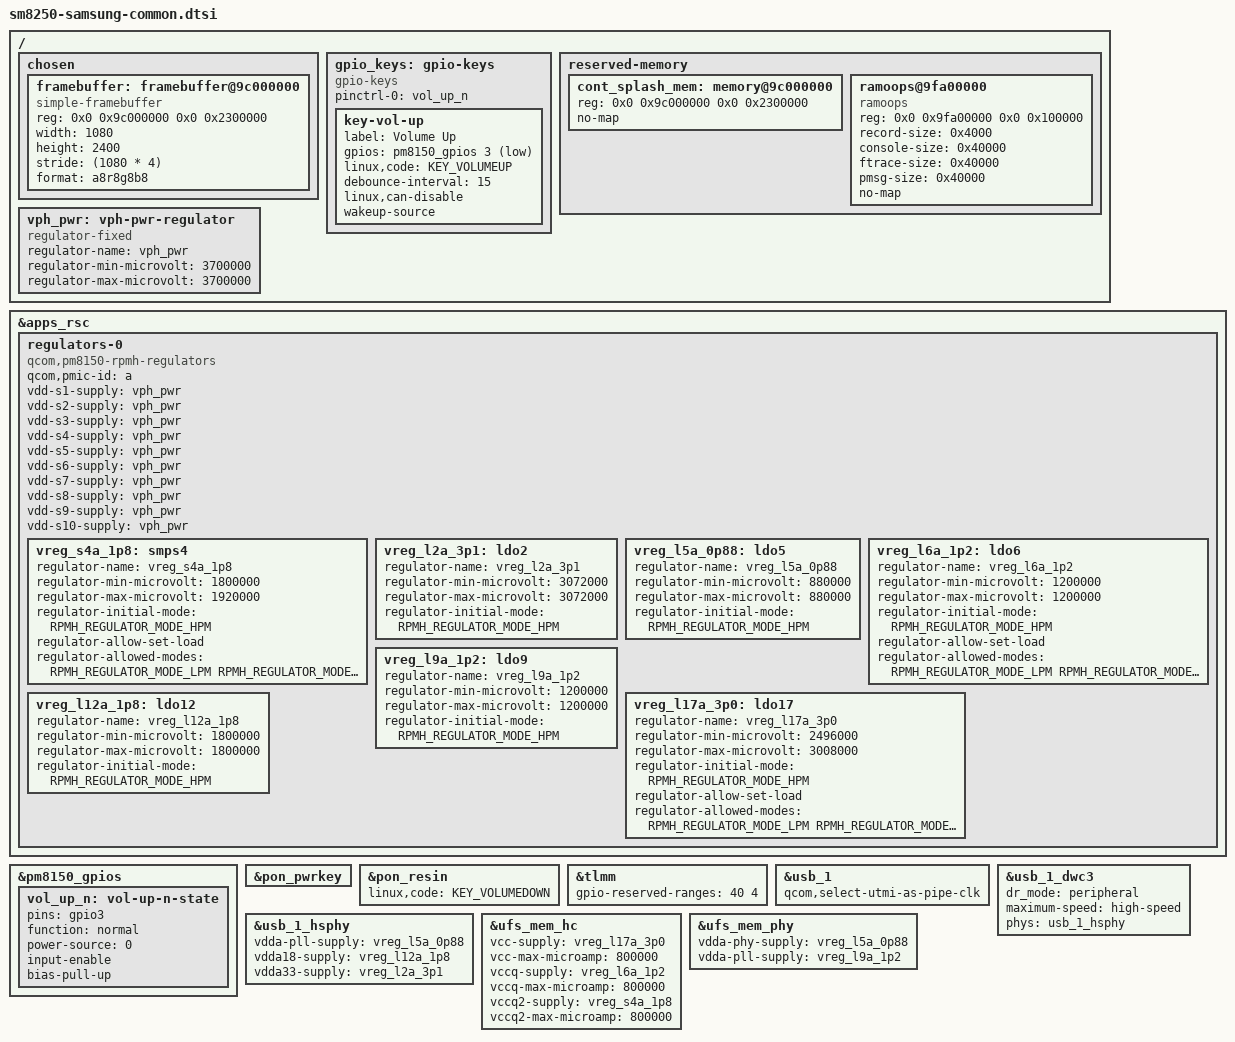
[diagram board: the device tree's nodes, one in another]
// SPDX-License-Identifier: GPL-2.0-only

/dts-v1/;

#include <dt-bindings/regulator/qcom,rpmh-regulator.h>
#include "sm8250.dtsi"
#include "pm8150.dtsi"

/ {
	chosen {
		#address-cells = <2>;
		#size-cells = <2>;
		ranges;

		framebuffer: framebuffer@9c000000 {
			compatible = "simple-framebuffer";
			reg = <0x0 0x9c000000 0x0 0x2300000>;
			width = <1080>;
			height = <2400>;
			stride = <(1080 * 4)>;
			format = "a8r8g8b8";
		};
	};

	gpio_keys: gpio-keys {
		compatible = "gpio-keys";

		pinctrl-names = "default";
		pinctrl-0 = <&vol_up_n>;

		key-vol-up {
			label = "Volume Up";
			gpios = <&pm8150_gpios 3 GPIO_ACTIVE_LOW>;
			linux,code = <KEY_VOLUMEUP>;
			debounce-interval = <15>;
			linux,can-disable;
			wakeup-source;
		};
	};

	reserved-memory {
		cont_splash_mem: memory@9c000000 {
			reg = <0x0 0x9c000000 0x0 0x2300000>;
			no-map;
		};

		ramoops@9fa00000 {
			compatible = "ramoops";
			reg = <0x0 0x9fa00000 0x0 0x100000>;
			record-size = <0x4000>;
			console-size = <0x40000>;
			ftrace-size = <0x40000>;
			pmsg-size = <0x40000>;
			no-map;
		};
	};

	vph_pwr: vph-pwr-regulator {
		compatible = "regulator-fixed";
		regulator-name = "vph_pwr";
		regulator-min-microvolt = <3700000>;
		regulator-max-microvolt = <3700000>;
	};
};

&apps_rsc {
	regulators-0 {
		compatible = "qcom,pm8150-rpmh-regulators";
		qcom,pmic-id = "a";

		vdd-s1-supply = <&vph_pwr>;
		vdd-s2-supply = <&vph_pwr>;
		vdd-s3-supply = <&vph_pwr>;
		vdd-s4-supply = <&vph_pwr>;
		vdd-s5-supply = <&vph_pwr>;
		vdd-s6-supply = <&vph_pwr>;
		vdd-s7-supply = <&vph_pwr>;
		vdd-s8-supply = <&vph_pwr>;
		vdd-s9-supply = <&vph_pwr>;
		vdd-s10-supply = <&vph_pwr>;

		vreg_s4a_1p8: smps4 {
			regulator-name = "vreg_s4a_1p8";
			regulator-min-microvolt = <1800000>;
			regulator-max-microvolt = <1920000>;
			regulator-initial-mode = <RPMH_REGULATOR_MODE_HPM>;
			regulator-allow-set-load;
			regulator-allowed-modes = <RPMH_REGULATOR_MODE_LPM
						   RPMH_REGULATOR_MODE_HPM>;
		};

		vreg_l2a_3p1: ldo2 {
			regulator-name = "vreg_l2a_3p1";
			regulator-min-microvolt = <3072000>;
			regulator-max-microvolt = <3072000>;
			regulator-initial-mode = <RPMH_REGULATOR_MODE_HPM>;
		};

		vreg_l5a_0p88: ldo5 {
			regulator-name = "vreg_l5a_0p88";
			regulator-min-microvolt = <880000>;
			regulator-max-microvolt = <880000>;
			regulator-initial-mode = <RPMH_REGULATOR_MODE_HPM>;
		};

		vreg_l6a_1p2: ldo6 {
			regulator-name = "vreg_l6a_1p2";
			regulator-min-microvolt = <1200000>;
			regulator-max-microvolt = <1200000>;
			regulator-initial-mode = <RPMH_REGULATOR_MODE_HPM>;
			regulator-allow-set-load;
			regulator-allowed-modes = <RPMH_REGULATOR_MODE_LPM
						   RPMH_REGULATOR_MODE_HPM>;
		};

		vreg_l9a_1p2: ldo9 {
			regulator-name = "vreg_l9a_1p2";
			regulator-min-microvolt = <1200000>;
			regulator-max-microvolt = <1200000>;
			regulator-initial-mode = <RPMH_REGULATOR_MODE_HPM>;
		};

		vreg_l12a_1p8: ldo12 {
			regulator-name = "vreg_l12a_1p8";
			regulator-min-microvolt = <1800000>;
			regulator-max-microvolt = <1800000>;
			regulator-initial-mode = <RPMH_REGULATOR_MODE_HPM>;
		};

		vreg_l17a_3p0: ldo17 {
			regulator-name = "vreg_l17a_3p0";
			regulator-min-microvolt = <2496000>;
			regulator-max-microvolt = <3008000>;
			regulator-initial-mode = <RPMH_REGULATOR_MODE_HPM>;
			regulator-allow-set-load;
			regulator-allowed-modes = <RPMH_REGULATOR_MODE_LPM
						   RPMH_REGULATOR_MODE_HPM>;
		};
	};
};

&pm8150_gpios {
	vol_up_n: vol-up-n-state {
		pins = "gpio3";
		function = "normal";
		power-source = <0>;
		input-enable;
		bias-pull-up;
	};
};

&pon_pwrkey {
	status = "okay";
};

&pon_resin {
	linux,code = <KEY_VOLUMEDOWN>;
	status = "okay";
};

&tlmm {
	gpio-reserved-ranges = <40 4>; /* I2C (Unused) */
};

&usb_1 {
	/* Limit to USB 2.0 for now */
	qcom,select-utmi-as-pipe-clk;

	status = "okay";
};

&usb_1_dwc3 {
	dr_mode = "peripheral";
	maximum-speed = "high-speed";
	/* Remove USB3 phy */
	phys = <&usb_1_hsphy>;
	phy-names = "usb2-phy";
};

&usb_1_hsphy {
	vdda-pll-supply = <&vreg_l5a_0p88>;
	vdda18-supply = <&vreg_l12a_1p8>;
	vdda33-supply = <&vreg_l2a_3p1>;

	status = "okay";
};

&ufs_mem_hc {
	vcc-supply = <&vreg_l17a_3p0>;
	vcc-max-microamp = <800000>;
	vccq-supply = <&vreg_l6a_1p2>;
	vccq-max-microamp = <800000>;
	vccq2-supply = <&vreg_s4a_1p8>;
	vccq2-max-microamp = <800000>;

	status = "okay";
};

&ufs_mem_phy {
	vdda-phy-supply = <&vreg_l5a_0p88>;
	vdda-pll-supply = <&vreg_l9a_1p2>;

	status = "okay";
};
